# PIC32MX470F512L register map
Registers are 32-bit, access not given, reset 0x0 unless marked. A register's access mark holds for its fields unless they carry their own. Offsets are from the block's base; [hi:lo] are bit positions; {n}, {i} and the like mark numbered series.

## PORTC — PORTC peripheral
Base 0xBF886200
0x00 ANSELC
0x04 ANSELCCLR
0x08 ANSELCSET
0x0C ANSELCINV
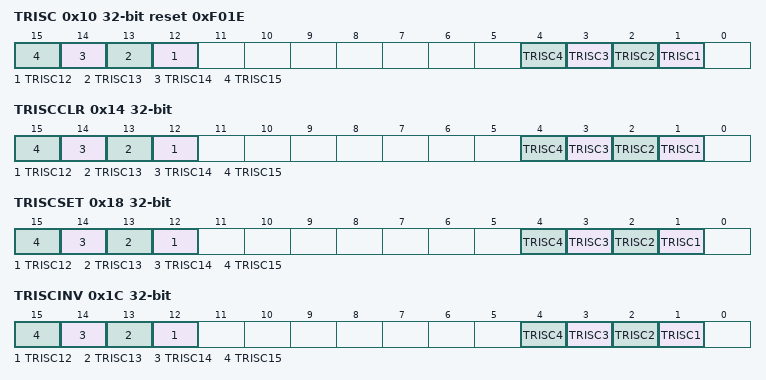
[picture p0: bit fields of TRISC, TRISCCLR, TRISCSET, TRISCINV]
0x10 TRISC reset 0xF01E
  [n] TRISC{n} (n=12..15), [n] TRISC{n} (n=1..4)
0x14 TRISCCLR
  [n] TRISC{n} (n=12..15), [n] TRISC{n} (n=1..4)
0x18 TRISCSET
  [n] TRISC{n} (n=12..15), [n] TRISC{n} (n=1..4)
0x1C TRISCINV
  [n] TRISC{n} (n=12..15), [n] TRISC{n} (n=1..4)
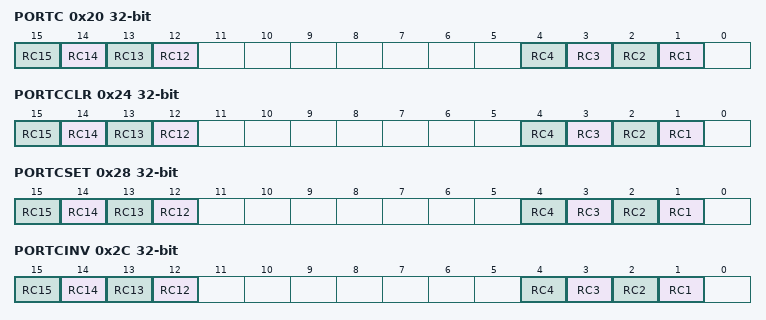
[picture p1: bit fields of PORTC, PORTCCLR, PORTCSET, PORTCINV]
0x20 PORTC
  [n] RC{n} (n=12..15), [n] RC{n} (n=1..4)
0x24 PORTCCLR
  [n] RC{n} (n=12..15), [n] RC{n} (n=1..4)
0x28 PORTCSET
  [n] RC{n} (n=12..15), [n] RC{n} (n=1..4)
0x2C PORTCINV
  [n] RC{n} (n=12..15), [n] RC{n} (n=1..4)
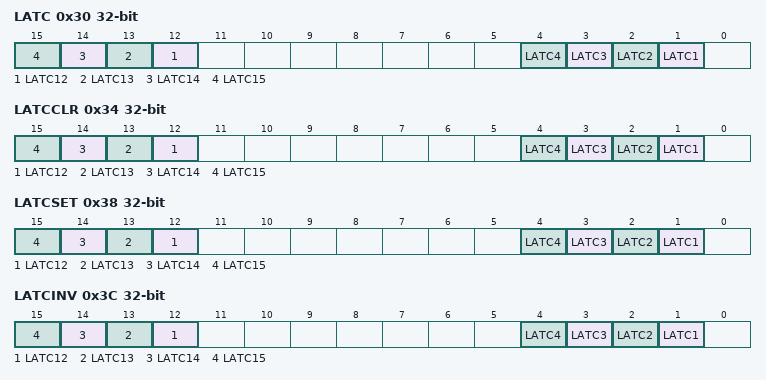
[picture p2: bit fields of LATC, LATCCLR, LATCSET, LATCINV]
0x30 LATC
  [n] LATC{n} (n=12..15), [n] LATC{n} (n=1..4)
0x34 LATCCLR
  [n] LATC{n} (n=12..15), [n] LATC{n} (n=1..4)
0x38 LATCSET
  [n] LATC{n} (n=12..15), [n] LATC{n} (n=1..4)
0x3C LATCINV
  [n] LATC{n} (n=12..15), [n] LATC{n} (n=1..4)
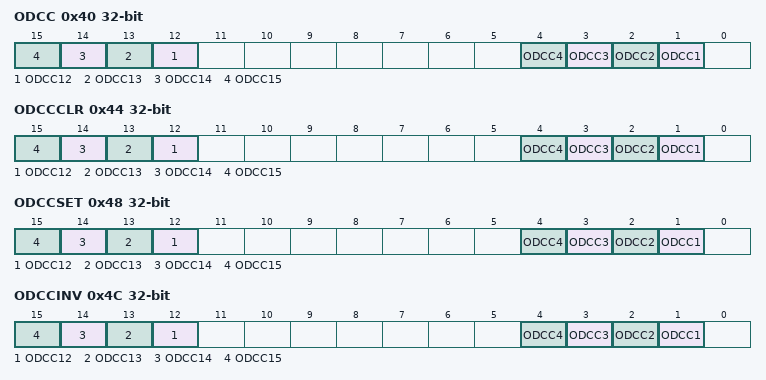
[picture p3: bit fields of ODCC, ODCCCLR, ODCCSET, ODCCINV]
0x40 ODCC
  [n] ODCC{n} (n=12..15), [n] ODCC{n} (n=1..4)
0x44 ODCCCLR
  [n] ODCC{n} (n=12..15), [n] ODCC{n} (n=1..4)
0x48 ODCCSET
  [n] ODCC{n} (n=12..15), [n] ODCC{n} (n=1..4)
0x4C ODCCINV
  [n] ODCC{n} (n=12..15), [n] ODCC{n} (n=1..4)
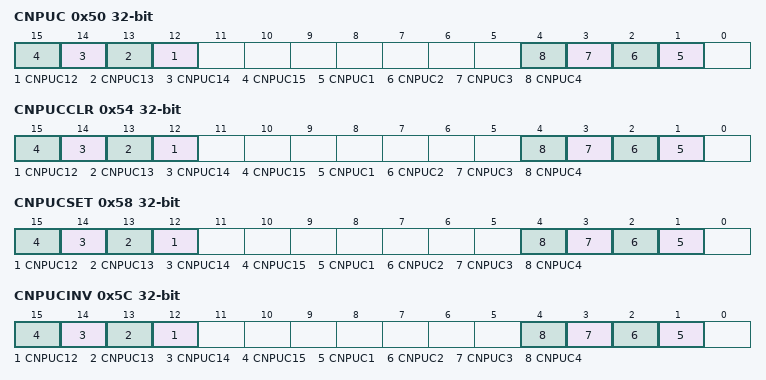
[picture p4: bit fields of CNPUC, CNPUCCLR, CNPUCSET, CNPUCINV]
0x50 CNPUC
  [n] CNPUC{n} (n=12..15), [n] CNPUC{n} (n=1..4)
0x54 CNPUCCLR
  [n] CNPUC{n} (n=12..15), [n] CNPUC{n} (n=1..4)
0x58 CNPUCSET
  [n] CNPUC{n} (n=12..15), [n] CNPUC{n} (n=1..4)
0x5C CNPUCINV
  [n] CNPUC{n} (n=12..15), [n] CNPUC{n} (n=1..4)
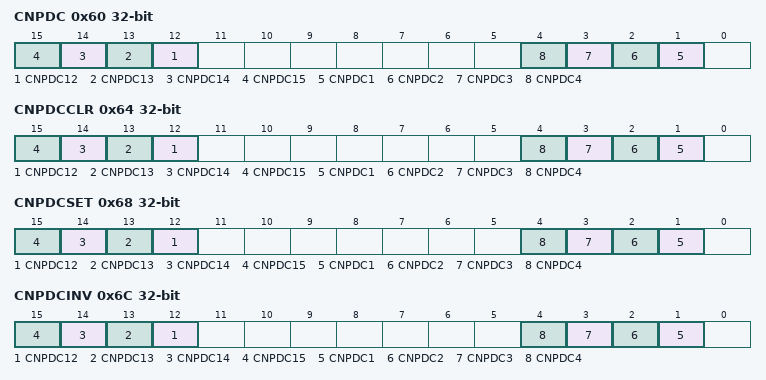
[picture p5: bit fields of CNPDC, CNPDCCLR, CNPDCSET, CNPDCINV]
0x60 CNPDC
  [n] CNPDC{n} (n=12..15), [n] CNPDC{n} (n=1..4)
0x64 CNPDCCLR
  [n] CNPDC{n} (n=12..15), [n] CNPDC{n} (n=1..4)
0x68 CNPDCSET
  [n] CNPDC{n} (n=12..15), [n] CNPDC{n} (n=1..4)
0x6C CNPDCINV
  [n] CNPDC{n} (n=12..15), [n] CNPDC{n} (n=1..4)
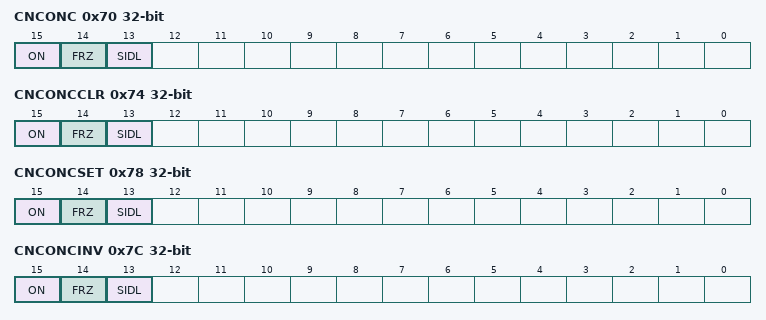
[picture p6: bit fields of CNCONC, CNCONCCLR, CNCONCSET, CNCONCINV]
0x70 CNCONC
  [15] ON, [14] FRZ, [13] SIDL
0x74 CNCONCCLR
  [15] ON, [14] FRZ, [13] SIDL
0x78 CNCONCSET
  [15] ON, [14] FRZ, [13] SIDL
0x7C CNCONCINV
  [15] ON, [14] FRZ, [13] SIDL
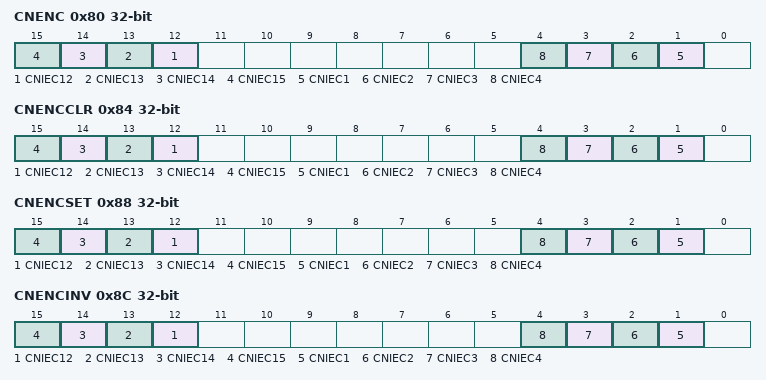
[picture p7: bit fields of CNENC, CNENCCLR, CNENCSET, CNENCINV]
0x80 CNENC
  [n] CNIEC{n} (n=12..15), [n] CNIEC{n} (n=1..4)
0x84 CNENCCLR
  [n] CNIEC{n} (n=12..15), [n] CNIEC{n} (n=1..4)
0x88 CNENCSET
  [n] CNIEC{n} (n=12..15), [n] CNIEC{n} (n=1..4)
0x8C CNENCINV
  [n] CNIEC{n} (n=12..15), [n] CNIEC{n} (n=1..4)
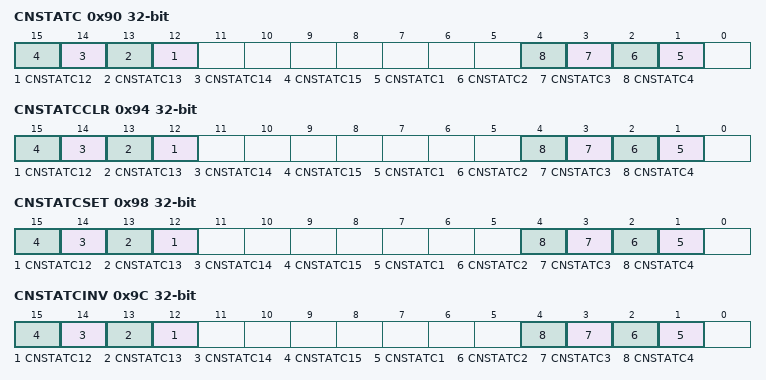
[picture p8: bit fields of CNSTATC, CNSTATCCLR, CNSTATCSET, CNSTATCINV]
0x90 CNSTATC
  [n] CNSTATC{n} (n=12..15), [n] CNSTATC{n} (n=1..4)
0x94 CNSTATCCLR
  [n] CNSTATC{n} (n=12..15), [n] CNSTATC{n} (n=1..4)
0x98 CNSTATCSET
  [n] CNSTATC{n} (n=12..15), [n] CNSTATC{n} (n=1..4)
0x9C CNSTATCINV
  [n] CNSTATC{n} (n=12..15), [n] CNSTATC{n} (n=1..4)

## PORTD — PORTD peripheral
Base 0xBF886300
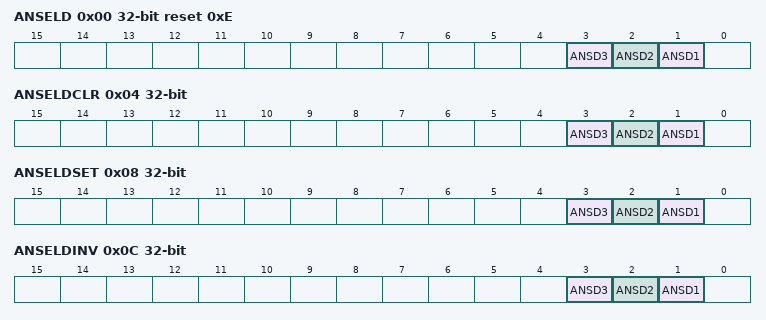
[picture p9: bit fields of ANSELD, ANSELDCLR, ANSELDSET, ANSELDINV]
0x00 ANSELD reset 0xE
  [3] ANSD3, [2] ANSD2, [1] ANSD1
0x04 ANSELDCLR
  [3] ANSD3, [2] ANSD2, [1] ANSD1
0x08 ANSELDSET
  [3] ANSD3, [2] ANSD2, [1] ANSD1
0x0C ANSELDINV
  [3] ANSD3, [2] ANSD2, [1] ANSD1
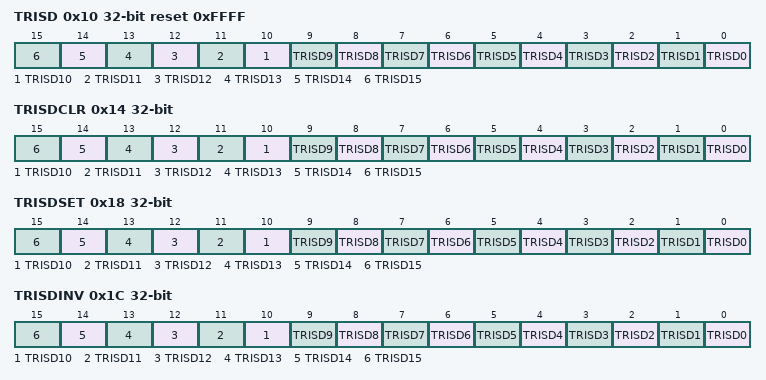
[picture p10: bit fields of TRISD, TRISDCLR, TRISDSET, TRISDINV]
0x10 TRISD reset 0xFFFF
  [n] TRISD{n} (n=0..15)
0x14 TRISDCLR
  [n] TRISD{n} (n=0..15)
0x18 TRISDSET
  [n] TRISD{n} (n=0..15)
0x1C TRISDINV
  [n] TRISD{n} (n=0..15)
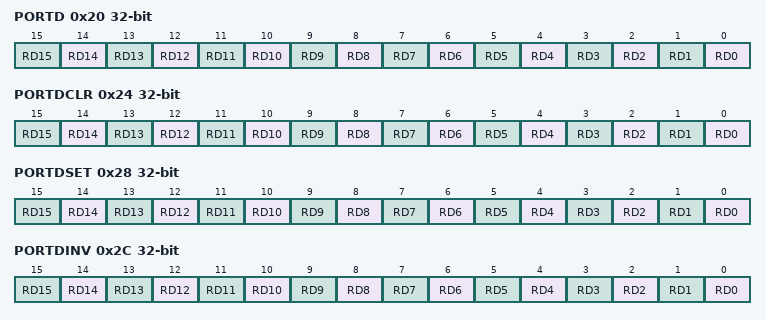
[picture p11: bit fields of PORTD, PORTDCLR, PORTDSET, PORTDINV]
0x20 PORTD
  [n] RD{n} (n=0..15)
0x24 PORTDCLR
  [n] RD{n} (n=0..15)
0x28 PORTDSET
  [n] RD{n} (n=0..15)
0x2C PORTDINV
  [n] RD{n} (n=0..15)
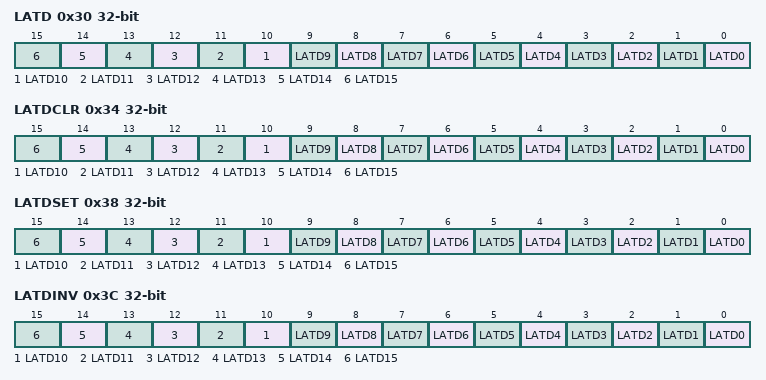
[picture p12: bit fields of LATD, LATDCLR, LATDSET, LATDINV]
0x30 LATD
  [n] LATD{n} (n=0..15)
0x34 LATDCLR
  [n] LATD{n} (n=0..15)
0x38 LATDSET
  [n] LATD{n} (n=0..15)
0x3C LATDINV
  [n] LATD{n} (n=0..15)
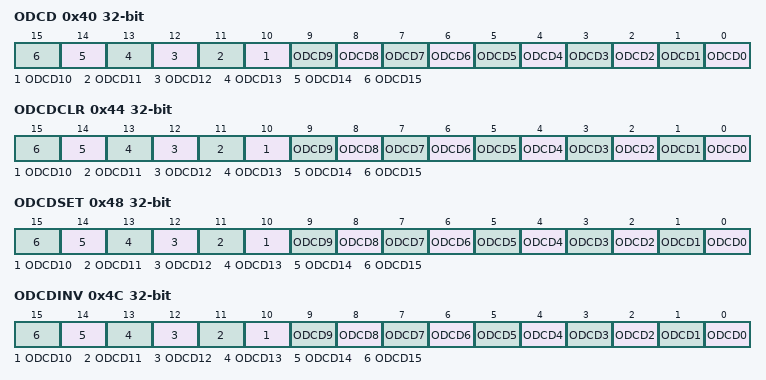
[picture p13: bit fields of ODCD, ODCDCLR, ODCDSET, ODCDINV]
0x40 ODCD
  [n] ODCD{n} (n=0..15)
0x44 ODCDCLR
  [n] ODCD{n} (n=0..15)
0x48 ODCDSET
  [n] ODCD{n} (n=0..15)
0x4C ODCDINV
  [n] ODCD{n} (n=0..15)
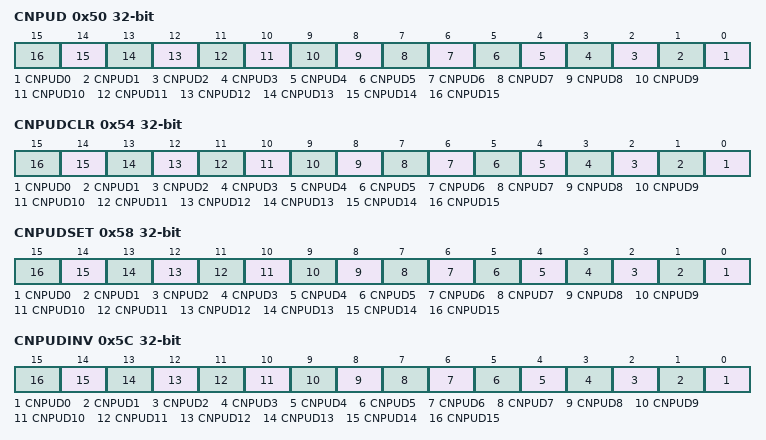
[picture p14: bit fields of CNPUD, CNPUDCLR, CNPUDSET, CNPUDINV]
0x50 CNPUD
  [n] CNPUD{n} (n=0..15)
0x54 CNPUDCLR
  [n] CNPUD{n} (n=0..15)
0x58 CNPUDSET
  [n] CNPUD{n} (n=0..15)
0x5C CNPUDINV
  [n] CNPUD{n} (n=0..15)
0x60 CNPDD
  [n] CNPDD{n} (n=0..15)
0x64 CNPDDCLR
  [n] CNPDD{n} (n=0..15)
0x68 CNPDDSET
  [n] CNPDD{n} (n=0..15)
0x6C CNPDDINV
  [n] CNPDD{n} (n=0..15)
0x70 CNCOND
  [15] ON, [14] FRZ, [13] SIDL
0x74 CNCONDCLR
  [15] ON, [14] FRZ, [13] SIDL
0x78 CNCONDSET
  [15] ON, [14] FRZ, [13] SIDL
0x7C CNCONDINV
  [15] ON, [14] FRZ, [13] SIDL
0x80 CNEND
  [n] CNIED{n} (n=0..15)
0x84 CNENDCLR
  [n] CNIED{n} (n=0..15)
0x88 CNENDSET
  [n] CNIED{n} (n=0..15)
0x8C CNENDINV
  [n] CNIED{n} (n=0..15)
0x90 CNSTATD
  [n] CNSTATD{n} (n=0..15)
0x94 CNSTATDCLR
  [n] CNSTATD{n} (n=0..15)
0x98 CNSTATDSET
  [n] CNSTATD{n} (n=0..15)
0x9C CNSTATDINV
  [n] CNSTATD{n} (n=0..15)
